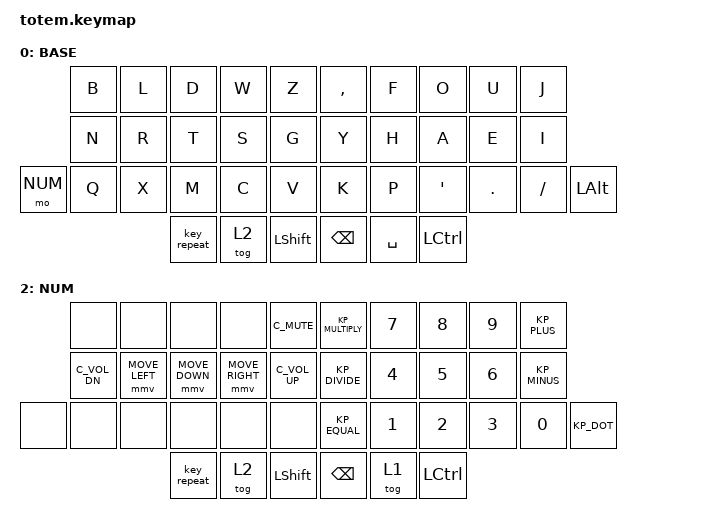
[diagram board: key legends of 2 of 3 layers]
//                                                        ▀▀▀▀▀     ▀▀▀▀▀          ▀▀█▀▀
//
//                                                        ▄▀▀▀▄  ▄  ▄▀▀▀▄  ▄  ▄▀▀▀▄  █  ▄▀▀▀▄
//                                                        █   █  █  █   █  █  █   █  █  █   █
//                                                         ▀▀▀   █   ▀▀▀   █   ▀▀▀   ▀   ▀▀▀
//                                                               █      ▄▄▄█▄▄▄    █   █  
//                                                               ▀      █  █  █     █▄█
//                                                             ▀▀▀▀▀    █  █  █      ▀
//                                                                      ▀  ▀  ▀
//
// ▄▄▄▄▄▄▄▄▄▄▄▄▄▄▄▄▄▄▄▄▄▄▄▄▄▄▄▄▄▄▄▄▄▄▄▄▄▄▄▄▄▄▄▄▄▄▄▄▄▄▄▄▄▄▄▄▄▄▄▄▄▄▄▄▄▄▄▄▄▄▄▄▄▄▄▄▄▄▄▄▄▄▄▄▄▄▄▄▄▄▄▄▄▄▄▄▄▄▄▄▄▄▄▄▄▄▄▄▄▄▄▄▄▄▄▄▄▄▄▄▄▄▄▄▄▄▄▄▄▄▄▄▄▄▄▄▄▄▄▄▄▄▄▄▄▄▄▄▄

#include <behaviors.dtsi>
#include <dt-bindings/zmk/bt.h>
#include <dt-bindings/zmk/keys.h>
#include <dt-bindings/zmk/outputs.h>

#define BASE 0
#define NAV  1
#define NUM  2

&mt {
    quick-tap-ms = <150>;
    flavor = "balanced";
    tapping-term-ms = <350>; //was 250
    retro-tap;
};

/ {
    combos { compatible = "zmk,combos"; };

    keymap {
        compatible = "zmk,keymap";

        // ▄▄▄▄▄▄▄▄▄▄▄▄▄▄▄▄▄▄▄▄▄▄▄▄▄▄▄▄▄▄▄▄▄▄▄▄▄▄▄▄▄▄▄▄▄▄▄▄▄▄▄▄▄▄▄▄▄▄▄▄▄▄▄▄▄▄▄▄▄▄▄▄▄▄▄▄▄▄▄▄▄▄▄▄▄▄▄▄▄▄▄▄▄▄▄▄▄▄▄▄▄▄▄▄▄▄▄▄▄▄▄▄▄▄▄▄▄▄▄▄▄▄▄▄▄▄▄▄▄▄▄▄▄▄▄▄▄▄▄▄▄▄▄▄▄▄▄▄▄

        base_layer {
            // ┏━━━━━━━━━━━━━━━━━━━━━━━━━━━━━━━━━━━━━━━┓

            label = "BASE";

            // ┗━━━━━━━━━━━━━━━━━━━━━━━━━━━━━━━━━━━━━━━┛
            //             ┏━━━━━━━━━━━┳━━━━━━━━━━━┳━━━━━━━━━━━┳━━━━━━━━━━━┳━━━━━━━━━━━┓   ┏━━━━━━━━━━━┳━━━━━━━━━━━┳━━━━━━━━━━━┳━━━━━━━━━━━┳━━━━━━━━━━━┓
            //             ┃     B     ┃     L     ┃     D     ┃     W     ┃     Z     ┃   ┃     ,     ┃     F     ┃     O     ┃     U     ┃     J     ┃
            //             ┣━━━━━━━━━━━╋━━━━━━━━━━━╋━━━━━━━━━━━╋━━━━━━━━━━━╋━━━━━━━━━━━┫   ┣━━━━━━━━━━━╋━━━━━━━━━━━╋━━━━━━━━━━━╋━━━━━━━━━━━╋━━━━━━━━━━━┫
            //             ┃     N     ┃     R     ┃     T     ┃     S     ┃     G     ┃   ┃     Y     ┃     H     ┃     A     ┃     E     ┃     I     ┃
            // ┏━━━━━━━━━━━╋━━━━━━━━━━━╋━━━━━━━━━━━╋━━━━━━━━━━━╋━━━━━━━━━━━╋━━━━━━━━━━━┫   ┣━━━━━━━━━━━╋━━━━━━━━━━━╋━━━━━━━━━━━╋━━━━━━━━━━━╋━━━━━━━━━━━╋━━━━━━━━━━━┓
            // ┃    Num    ┃     Q     ┃     X     ┃     M     ┃     C     ┃     V     ┃   ┃     K     ┃     P     ┃     '     ┃     .     ┃     /     ┃    ALT    ┃
            // ┗━━━━━━━━━━━┻━━━━━━━━━━━┻━━━━━━━━━━━╋━━━━━━━━━━━╋━━━━━━━━━━━╋━━━━━━━━━━━┫   ┣━━━━━━━━━━━╋━━━━━━━━━━━╋━━━━━━━━━━━╋━━━━━━━━━━━┻━━━━━━━━━━━┻━━━━━━━━━━━┛
            //                                     ┃   REPEAT  ┃    SW3    ┃   SHFT    ┃   ┃   BACK    ┃   SPACE   ┃   CTRL    ┃
            //                                     ┗━━━━━━━━━━━┻━━━━━━━━━━━┻━━━━━━━━━━━┛   ┗━━━━━━━━━━━┻━━━━━━━━━━━┻━━━━━━━━━━━┛

            bindings = <
                 &kp B  &kp L               &kp D            &kp W           &kp Z                   &kp COMMA             &kp F            &kp O            &kp U    &kp J
                 &kp N  &kp R               &kp T            &kp S           &kp G                   &kp Y                 &kp H            &kp A            &kp E    &kp I
         &mo NUM &kp Q  &kp X               &kp M            &kp C           &kp V                   &kp K                 &kp P            &kp APOSTROPHE   &kp DOT  &kp FSLH  &kp LALT
                                            &key_repeat      &tog 2          &kp LSHIFT              &kp BSPC              &kp SPACE        &kp LCTRL
            >;
        };

        // ▄▄▄▄▄▄▄▄▄▄▄▄▄▄▄▄▄▄▄▄▄▄▄▄▄▄▄▄▄▄▄▄▄▄▄▄▄▄▄▄▄▄▄▄▄▄▄▄▄▄▄▄▄▄▄▄▄▄▄▄▄▄▄▄▄▄▄▄▄▄▄▄▄▄▄▄▄▄▄▄▄▄▄▄▄▄▄▄▄▄▄▄▄▄▄▄▄▄▄▄▄▄▄▄▄▄▄▄▄▄▄▄▄▄▄▄▄▄▄▄▄▄▄▄▄▄▄▄▄▄▄▄▄▄▄▄▄▄▄▄▄▄▄▄▄▄▄▄▄

        nav_layer {
            // ┏━━━━━━━━━━━━━━━━━━━━━━━━━━━━━━━━━━━━━━━┓

            label = "NAVI";

            // ┗━━━━━━━━━━━━━━━━━━━━━━━━━━━━━━━━━━━━━━━┛
            //             ┏━━━━━━━━━━━┳━━━━━━━━━━━┳━━━━━━━━━━━┳━━━━━━━━━━━┳━━━━━━━━━━━┓   ┏━━━━━━━━━━━┳━━━━━━━━━━━┳━━━━━━━━━━━┳━━━━━━━━━━━┳━━━━━━━━━━━┓
            //             ┃ C + S Tab ┃  C Tab    ┃     UP    ┃           ┃    RMB    ┃   ┃           ┃    HOME   ┃  C PgDn   ┃  C PgUp   ┃    END    ┃
            //             ┣━━━━━━━━━━━╋━━━━━━━━━━━╋━━━━━━━━━━━╋━━━━━━━━━━━╋━━━━━━━━━━━┫   ┣━━━━━━━━━━━╋━━━━━━━━━━━╋━━━━━━━━━━━╋━━━━━━━━━━━╋━━━━━━━━━━━┫
            //             ┃           ┃   LEFT    ┃    DOWN   ┃   RIGHT   ┃    LMB    ┃   ┃           ┃    LEFT   ┃   DOWN    ┃    UP     ┃   RIGHT   ┃
            // ┏━━━━━━━━━━━╋━━━━━━━━━━━╋━━━━━━━━━━━╋━━━━━━━━━━━╋━━━━━━━━━━━╋━━━━━━━━━━━┫   ┣━━━━━━━━━━━╋━━━━━━━━━━━╋━━━━━━━━━━━╋━━━━━━━━━━━╋━━━━━━━━━━━╋━━━━━━━━━━━┓
            // ┃           ┃   UNDO    ┃   CUT     ┃    COPY   ┃   PASTE   ┃    REDO   ┃   ┃           ┃   W LEFT  ┃   W DOWN  ┃   W UP    ┃  W RIGHT  ┃           ┃
            // ┗━━━━━━━━━━━┻━━━━━━━━━━━┻━━━━━━━━━━━╋━━━━━━━━━━━╋━━━━━━━━━━━╋━━━━━━━━━━━┫   ┣━━━━━━━━━━━╋━━━━━━━━━━━╋━━━━━━━━━━━╋━━━━━━━━━━━┻━━━━━━━━━━━┻━━━━━━━━━━━┛
            //                                     ┃   REPEAT  ┃    SW3    ┃   SHFT    ┃   ┃   BACK    ┃   SW1     ┃   CTRL    ┃
            //                                     ┗━━━━━━━━━━━┻━━━━━━━━━━━┻━━━━━━━━━━━┛   ┗━━━━━━━━━━━┻━━━━━━━━━━━┻━━━━━━━━━━━┛


            bindings = <
// ╷           ╷           ╷           ╷           ╷           ╷           ╷   ╷           ╷           ╷           ╷           ╷           ╷           ╷


            bindings = <
// ╷           ╷           ╷           ╷           ╷           ╷           ╷   ╷           ╷           ╷           ╷           ╷           ╷           ╷

                &none       &none      &mmv MOVE_UP &none       &mkp RCLK       &none       &kp HOME    &none       &none       &kp END
                &none   &mmv MOVE_LEFT &mmv MOVE_DOWN &mmv MOVE_RIGHT &mkp LCLK &none       &kp LEFT    &kp DOWN    &kp UP      &kp RIGHT
    &none      &kp LC(Z)    &kp LC(X)  &kp LC(C)    &kp LC(V)   &kp LC(Y)       &none       &msc SCRL_LEFT   &msc SCRL_DOWN &msc SCRL_UP &msc SCRL_RIGHT &none
                                       &key_repeat  &tog 2      &kp LSHIFT      &kp BSPC    &tog 1      &kp LCTRL
                        >;
                };

        // ▄▄▄▄▄▄▄▄▄▄▄▄▄▄▄▄▄▄▄▄▄▄▄▄▄▄▄▄▄▄▄▄▄▄▄▄▄▄▄▄▄▄▄▄▄▄▄▄▄▄▄▄▄▄▄▄▄▄▄▄▄▄▄▄▄▄▄▄▄▄▄▄▄▄▄▄▄▄▄▄▄▄▄▄▄▄▄▄▄▄▄▄▄▄▄▄▄▄▄▄▄▄▄▄▄▄▄▄▄▄▄▄▄▄▄▄▄▄▄▄▄▄▄▄▄▄▄▄▄▄▄▄▄▄▄▄▄▄▄▄▄▄▄▄▄▄▄▄▄

        num_layer {
            // ┏━━━━━━━━━━━━━━━━━━━━━━━━━━━━━━━━━━━━━━━┓

            label = "NUM";

            // ┗━━━━━━━━━━━━━━━━━━━━━━━━━━━━━━━━━━━━━━━┛
            //             ┏━━━━━━━━━━━┳━━━━━━━━━━━┳━━━━━━━━━━━┳━━━━━━━━━━━┳━━━━━━━━━━━┓   ┏━━━━━━━━━━━┳━━━━━━━━━━━┳━━━━━━━━━━━┳━━━━━━━━━━━┳━━━━━━━━━━━┓
            //             ┃           ┃           ┃   EMAIL2  ┃   EMAIL1  ┃   MUTE    ┃   ┃     *     ┃     7     ┃     8     ┃     9     ┃     +     ┃
            //             ┣━━━━━━━━━━━╋━━━━━━━━━━━╋━━━━━━━━━━━╋━━━━━━━━━━━╋━━━━━━━━━━━┫   ┣━━━━━━━━━━━╋━━━━━━━━━━━╋━━━━━━━━━━━╋━━━━━━━━━━━╋━━━━━━━━━━━┫
            //             ┃     VOL-  ┃   PREV    ┃    PLAY   ┃   NEXT    ┃    VOL+   ┃   ┃     /     ┃     4     ┃     5     ┃     6     ┃     -     ┃
            // ┏━━━━━━━━━━━╋━━━━━━━━━━━╋━━━━━━━━━━━╋━━━━━━━━━━━╋━━━━━━━━━━━╋━━━━━━━━━━━┫   ┣━━━━━━━━━━━╋━━━━━━━━━━━╋━━━━━━━━━━━╋━━━━━━━━━━━╋━━━━━━━━━━━╋━━━━━━━━━━━┓
            // ┃           ┃           ┃           ┃           ┃           ┃           ┃   ┃     =     ┃     1     ┃     2     ┃     3     ┃     0     ┃     .     ┃
            // ┗━━━━━━━━━━━┻━━━━━━━━━━━┻━━━━━━━━━━━╋━━━━━━━━━━━╋━━━━━━━━━━━╋━━━━━━━━━━━┫   ┣━━━━━━━━━━━╋━━━━━━━━━━━╋━━━━━━━━━━━╋━━━━━━━━━━━┻━━━━━━━━━━━┻━━━━━━━━━━━┛
            //                                     ┃   REPEAT  ┃    SW3    ┃   SHFT    ┃   ┃   BACK    ┃   SW 1    ┃   CTRL    ┃
            //                                     ┗━━━━━━━━━━━┻━━━━━━━━━━━┻━━━━━━━━━━━┛   ┗━━━━━━━━━━━┻━━━━━━━━━━━┻━━━━━━━━━━━┛

            bindings = <
                 &none  &none               &none            &none           &C_MUTE                 &KP_MULTIPLY          &kp N7           &kp N8           &kp N9   &KP_PLUS
              &C_VOL_DN &mmv MOVE_LEFT      &mmv MOVE_DOWN   &mmv MOVE_RIGHT &C_VOL_UP               &KP_DIVIDE            &kp N4           &kp N5           &kp N6   &KP_MINUS
        &none &none  &none                  &none            &none           &none                   &KP_EQUAL             &kp N1           &kp N2           &kp N3   &kp N0   &KP_DOT
                                            &key_repeat      &tog 2          &kp LSHIFT              &kp BSPC              &tog 1           &kp LCTRL
            >;
        };
    };
};
